VERSION "1.0"

NS_ :

BS_:
BU_: MOCK_SENSOR_NODE GCS

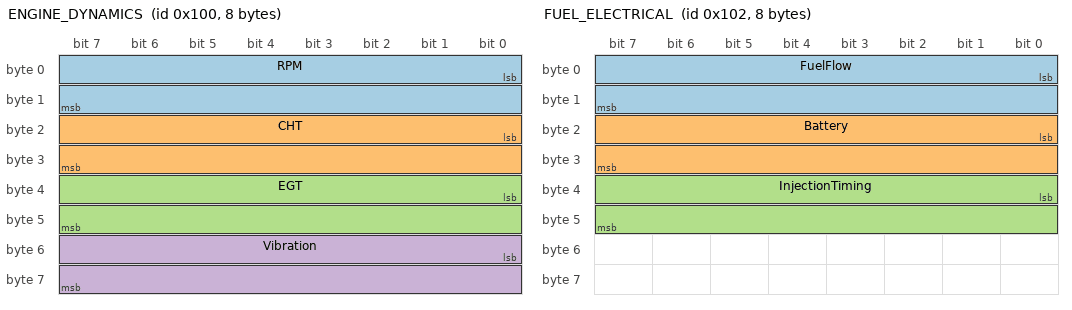
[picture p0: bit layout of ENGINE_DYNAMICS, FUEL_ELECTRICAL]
BO_ 256 ENGINE_DYNAMICS: 8 MOCK_SENSOR_NODE
 SG_ RPM : 0|16@1+ (1,0) [0|65535] "rpm" GCS
 SG_ CHT : 16|16@1+ (0.1,0) [0|6553.5] "degC" GCS
 SG_ EGT : 32|16@1+ (0.1,0) [0|6553.5] "degC" GCS
 SG_ Vibration : 48|16@1+ (0.01,0) [0|655.35] "mm/s" GCS

BO_ 257 LUBRICATION: 8 MOCK_SENSOR_NODE
 SG_ OilPressure : 0|16@1+ (0.01,0) [0|655.35] "bar" GCS
 SG_ OilTemp : 16|16@1+ (0.1,0) [0|6553.5] "degC" GCS

BO_ 258 FUEL_ELECTRICAL: 8 MOCK_SENSOR_NODE
 SG_ FuelFlow : 0|16@1+ (0.1,0) [0|6553.5] "L/h" GCS
 SG_ Battery : 16|16@1+ (0.01,0) [0|655.35] "V" GCS
 SG_ InjectionTiming : 32|16@1+ (0.01,0) [0|655.35] "deg" GCS

CM_ BO_ 256 "Mock engine dynamics telemetry for software-only bench testing.";
CM_ BO_ 257 "Mock lubrication telemetry for software-only bench testing.";
CM_ BO_ 258 "Mock fuel/electrical telemetry for software-only bench testing.";
